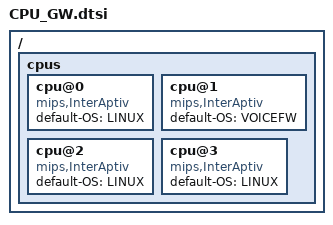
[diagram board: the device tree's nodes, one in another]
/ {
       cpus {
                cpu@0 {
                        compatible = "mips,InterAptiv";
                        default-OS = "LINUX";
                };
                cpu@1 {
                        compatible = "mips,InterAptiv";
                        default-OS = "VOICEFW";
                };
                cpu@2 {
                        compatible = "mips,InterAptiv";
                        default-OS = "LINUX";
                };
                cpu@3 {
                        compatible = "mips,InterAptiv";
                        default-OS = "LINUX";
                };
        };
};
